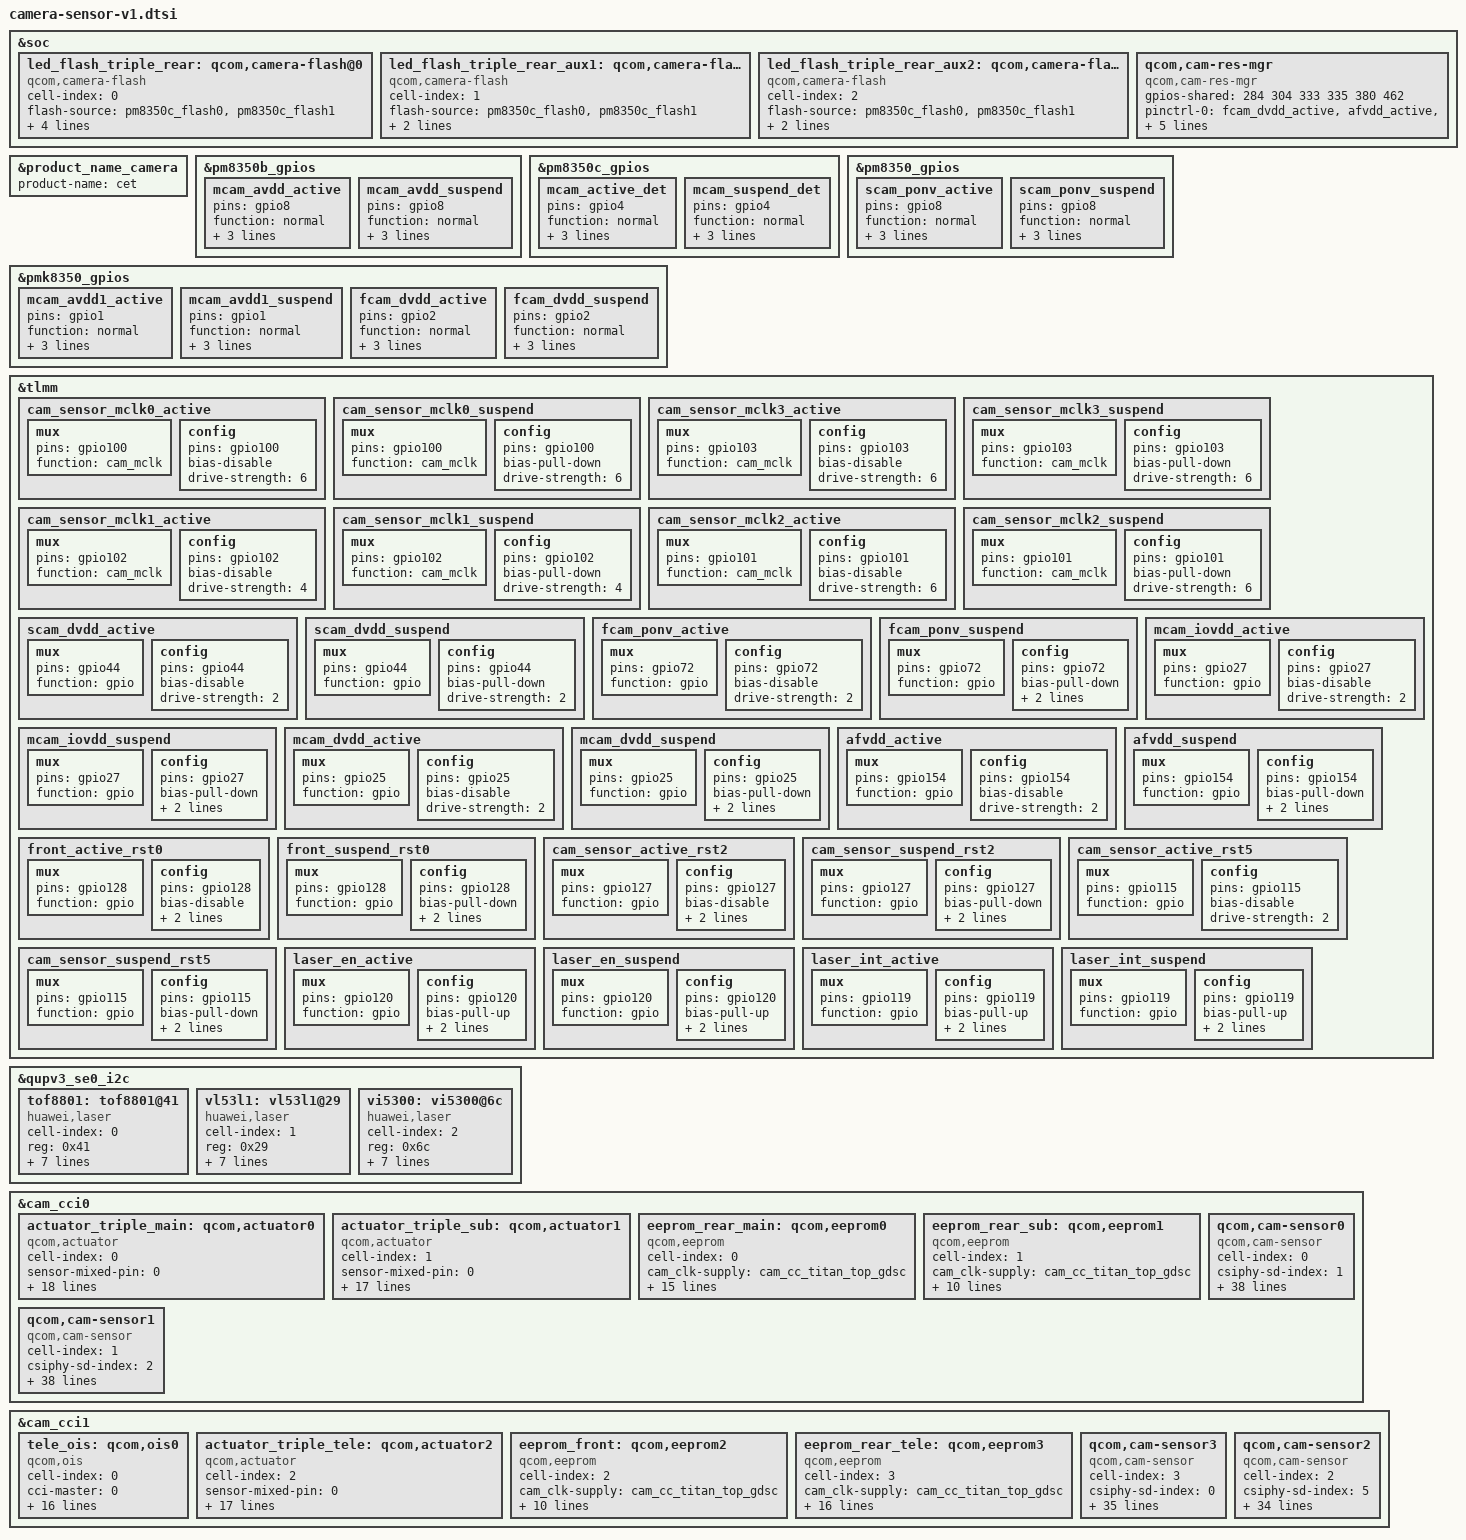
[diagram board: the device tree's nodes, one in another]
#include <dt-bindings/clock/qcom,camcc-lahaina.h>

&soc {
	led_flash_triple_rear: qcom,camera-flash@0 {
		cell-index = <0>;
		compatible = "qcom,camera-flash";
		flash-source = <&pm8350c_flash0 &pm8350c_flash1>;
		torch-source = <&pm8350c_torch0 &pm8350c_torch1>;
		switch-source = <&pm8350c_switch2>;
		torch-light-num = <0 1>;
		torch-light-name = "torch-light0", "torch-light1";
		status = "ok";
	};

	led_flash_triple_rear_aux1: qcom,camera-flash@1 {
		cell-index = <1>;
		compatible = "qcom,camera-flash";
		flash-source = <&pm8350c_flash0 &pm8350c_flash1>;
		torch-source = <&pm8350c_torch0 &pm8350c_torch1>;
		switch-source = <&pm8350c_switch2>;
		status = "ok";
	};

	led_flash_triple_rear_aux2: qcom,camera-flash@2 {
		cell-index = <2>;
		compatible = "qcom,camera-flash";
		flash-source = <&pm8350c_flash0 &pm8350c_flash1>;
		torch-source = <&pm8350c_torch0 &pm8350c_torch1>;
		switch-source = <&pm8350c_switch2>;
		status = "ok";
	};

	qcom,cam-res-mgr {
		compatible = "qcom,cam-res-mgr";
		status = "ok";
		gpios-shared = <284 304 333 335 380 462>;
		pinctrl-names = "cam_active", "cam_suspend";
		pinctrl-0 = <&fcam_dvdd_active
					&afvdd_active
					&mcam_dvdd_active
					&mcam_iovdd_active
					&mcam_avdd_active
					&mcam_avdd1_active>;
		pinctrl-1 = <&fcam_dvdd_suspend
					&afvdd_suspend
					&mcam_dvdd_suspend
					&mcam_iovdd_suspend
					&mcam_avdd_suspend
					&mcam_avdd1_suspend>;
	};
};

&product_name_camera {
    product-name = "cet";
};

&pm8350b_gpios {
	mcam_avdd_active: mcam_avdd_active {
		pins = "gpio8";
		function = "normal";
		bias-disable;
		output-high;
		power-source = <0>;
	};
	mcam_avdd_suspend: mcam_avdd_suspend {
		pins = "gpio8";
		function = "normal";
		bias-disable;
		output-low;
		power-source = <0>;
	};
};

&pm8350c_gpios{
	mcam_active_det: mcam_active_det {
		pins = "gpio4";
		function = "normal";
		bias-disable;
		drive-strength = <2>;
		input-enable;
	};
	mcam_suspend_det: mcam_suspend_det {
		pins = "gpio4";
		function = "normal";
		bias-disable;
		drive-strength = <2>;
		input-enable;
	};
};

&pm8350_gpios {
	scam_ponv_active: scam_ponv_active {
		pins = "gpio8";
		function = "normal";
		bias-disable;
		output-high;
		power-source = <0>;
	};
	scam_ponv_suspend: scam_ponv_suspend {
		pins = "gpio8";
		function = "normal";
		bias-disable;
		output-low;
		power-source = <0>;
	};
};

&pmk8350_gpios {
	mcam_avdd1_active: mcam_avdd1_active {
		pins = "gpio1";
		function = "normal";
		bias-disable;
		output-high;
		power-source = <0>;
	};
	mcam_avdd1_suspend: mcam_avdd1_suspend {
		pins = "gpio1";
		function = "normal";
		bias-disable;
		output-low;
		power-source = <0>;
	};

	fcam_dvdd_active: fcam_dvdd_active {
		pins = "gpio2";
		function = "normal";
		bias-disable;
		output-high;
		power-source = <0>;
	};
	fcam_dvdd_suspend: fcam_dvdd_suspend {
		pins = "gpio2";
		function = "normal";
		bias-disable;
		output-low;
		power-source = <0>;
	};
};

&tlmm {
	cam_sensor_mclk0_active: cam_sensor_mclk0_active {
		/* MCLK0 */
		mux {
			pins = "gpio100";
			function = "cam_mclk";
		};

		config {
			pins = "gpio100";
			bias-disable; /* No PULL */
			drive-strength = <6>; /* 2 MA */
		};
	};

	cam_sensor_mclk0_suspend: cam_sensor_mclk0_suspend {
		/* MCLK0 */
		mux {
			pins = "gpio100";
			function = "cam_mclk";
		};

		config {
			pins = "gpio100";
			bias-pull-down; /* PULL DOWN */
			drive-strength = <6>; /* 2 MA */
		};
	};

	cam_sensor_mclk3_active: cam_sensor_mclk3_active {
		/* MCLK3 */
		mux {
			pins = "gpio103";
			function = "cam_mclk";
		};

		config {
			pins = "gpio103";
			bias-disable; /* No PULL */
			drive-strength = <6>; /* 2 MA */
		};
	};

	cam_sensor_mclk3_suspend: cam_sensor_mclk3_suspend {
		/* MCLK3 */
		mux {
			pins = "gpio103";
			function = "cam_mclk";
		};

		config {
			pins = "gpio103";
			bias-pull-down; /* PULL DOWN */
			drive-strength = <6>; /* 2 MA */
		};
	};

	cam_sensor_mclk1_active: cam_sensor_mclk1_active {
		/* MCLK1 */
		mux {
			pins = "gpio102";
			function = "cam_mclk";
		};

		config {
			pins = "gpio102";
			bias-disable; /* No PULL */
			drive-strength = <4>; /* 2 MA */
		};
	};

	cam_sensor_mclk1_suspend: cam_sensor_mclk1_suspend {
		/* MCLK1 */
		mux {
			pins = "gpio102";
			function = "cam_mclk";
		};

		config {
			pins = "gpio102";
			bias-pull-down; /* PULL DOWN */
			drive-strength = <4>; /* 2 MA */
		};
	};

	cam_sensor_mclk2_active: cam_sensor_mclk2_active {
		/* MCLK2 */
		mux {
			pins = "gpio101";
			function = "cam_mclk";
		};

		config {
			pins = "gpio101";
			bias-disable; /* No PULL */
			drive-strength = <6>; /* 2 MA */
		};
	};

	cam_sensor_mclk2_suspend: cam_sensor_mclk2_suspend {
		/* MCLK2 */
		mux {
			pins = "gpio101";
			function = "cam_mclk";
		};

		config {
			pins = "gpio101";
			bias-pull-down; /* PULL DOWN */
			drive-strength = <6>; /* 2 MA */
		};
	};

	scam_dvdd_active: scam_dvdd_active {
		/* DVDD 0-for main */
		mux {
			pins = "gpio44";
			function = "gpio";
		};

		config {
			pins = "gpio44";
			bias-disable; /* No PULL */
			drive-strength = <2>; /* 2 MA */
		};
	};

	scam_dvdd_suspend: scam_dvdd_suspend {
		/* DVDD 0-for main */
		mux {
			pins = "gpio44";
			function = "gpio";
		};

		config {
			pins = "gpio44";
			bias-pull-down; /* PULL DOWN */
			drive-strength = <2>; /* 2 MA */
		};
	};


	fcam_ponv_active: fcam_ponv_active {
		/* fcam ponv */
		mux {
			pins = "gpio72";
			function = "gpio";
		};

		config {
			pins = "gpio72";
			bias-disable; /* No PULL */
			drive-strength = <2>; /* 2 MA */
		};
	};

	fcam_ponv_suspend: fcam_ponv_suspend {
		/* fcam ponv */
		mux {
			pins = "gpio72";
			function = "gpio";
		};

		config {
			pins = "gpio72";
			bias-pull-down; /* PULL DOWN */
			drive-strength = <2>; /* 2 MA */
			output-low;
		};
	};

	mcam_iovdd_active: mcam_iovdd_active {
		mux {
			pins = "gpio27";
			function = "gpio";
		};

		config {
			pins = "gpio27";
			bias-disable; /* No PULL */
			drive-strength = <2>; /* 2 MA */
		};
	};

	mcam_iovdd_suspend: mcam_iovdd_suspend {
		mux {
			pins = "gpio27";
			function = "gpio";
		};

		config {
			pins = "gpio27";
			bias-pull-down; /* PULL DOWN */
			drive-strength = <2>; /* 2 MA */
			output-low;
		};
	};

	mcam_dvdd_active: mcam_dvdd_active {
		mux {
			pins = "gpio25";
			function = "gpio";
		};

		config {
			pins = "gpio25";
			bias-disable; /* No PULL */
			drive-strength = <2>; /* 2 MA */
		};
	};

	mcam_dvdd_suspend: mcam_dvdd_suspend {
		mux {
			pins = "gpio25";
			function = "gpio";
		};

		config {
			pins = "gpio25";
			bias-pull-down; /* PULL DOWN */
			drive-strength = <2>; /* 2 MA */
			output-low;
		};
	};

	afvdd_active: afvdd_active {
		mux {
			pins = "gpio154";
			function = "gpio";
		};

		config {
			pins = "gpio154";
			bias-disable; /* No PULL */
			drive-strength = <2>; /* 2 MA */
		};
	};

	afvdd_suspend: afvdd_suspend {
		mux {
			pins = "gpio154";
			function = "gpio";
		};

		config {
			pins = "gpio154";
			bias-pull-down; /* PULL DOWN */
			drive-strength = <2>; /* 2 MA */
			output-low;
		};
	};

	front_active_rst0: front_active_rst0 {
		/* RESET 0 */
		mux {
			pins = "gpio128";
			function = "gpio";
		};

		config {
			pins = "gpio128";
			bias-disable; /* No PULL */
			drive-strength = <2>; /* 2 MA */
			input-enable;
		};
	};

	front_suspend_rst0: front_suspend_rst0 {
		/* RESET 0 */
		mux {
			pins = "gpio128";
			function = "gpio";
		};

		config {
			pins = "gpio128";
			bias-pull-down; /* PULL DOWN */
			drive-strength = <2>; /* 2 MA */
			output-low;
		};
	};

	cam_sensor_active_rst2: cam_sensor_active_rst2 {
		/* RESET 2 */
		mux {
			pins = "gpio127";
			function = "gpio";
		};

		config {
			pins = "gpio127";
			bias-disable; /* No PULL */
			drive-strength = <2>; /* 2 MA */
			input-enable;
		};
	};

	cam_sensor_suspend_rst2: cam_sensor_suspend_rst2 {
		/* RESET 2 */
		mux {
			pins = "gpio127";
			function = "gpio";
		};

		config {
			pins = "gpio127";
			bias-pull-down; /* PULL DOWN */
			drive-strength = <2>; /* 2 MA */
			output-low;
		};
	};

	cam_sensor_active_rst5: cam_sensor_active_rst5 {
		/* RESET 5 */
		mux {
			pins = "gpio115";
			function = "gpio";
		};

		config {
			pins = "gpio115";
			bias-disable; /* No PULL */
			drive-strength = <2>; /* 2 MA */
		};
	};

	cam_sensor_suspend_rst5: cam_sensor_suspend_rst5 {
		/* RESET 2 */
		mux {
			pins = "gpio115";
			function = "gpio";
		};

		config {
			pins = "gpio115";
			bias-pull-down; /* PULL DOWN */
			drive-strength = <2>; /* 2 MA */
			output-low;
		};
	};

	laser_en_active: laser_en_active {
		/* laser en pin */
		mux {
			pins = "gpio120";
			function = "gpio";
		};

		config {
			pins = "gpio120";
			bias-pull-up; /* PULL UP */
			drive-strength = <2>; /* 2 MA */
			input-enable;
		};
	};

	laser_en_suspend: laser_en_suspend {
		/* laser en pin */
		mux {
			pins = "gpio120";
			function = "gpio";
		};

		config {
			pins = "gpio120";
			bias-pull-up; /* PULL UP */
			drive-strength = <2>; /* 2 MA */
			input-enable;
		};
	};

	laser_int_active: laser_int_active {
		/* laser int pin */
		mux {
			pins = "gpio119";
			function = "gpio";
		};

		config {
			pins = "gpio119";
			bias-pull-up; /* PULL UP */
			drive-strength = <2>; /* 2 MA */
			input-enable;
		};
	};

	laser_int_suspend: laser_int_suspend {
		/* laser int pin */
		mux {
			pins = "gpio119";
			function = "gpio";
		};

		config {
			pins = "gpio119";
			bias-pull-up; /* PULL UP */
			drive-strength = <2>; /* 2 MA */
			input-enable;
		};
	};
};

/* laser */
&qupv3_se0_i2c {
	status = "ok";
	#address-cells = <1>;
	#size-cells = <0>;

	tof8801: tof8801@41 {
		cell-index = <0>;
		compatible = "huawei,laser";
		reg = <0x41>;
		vdd_ana-supply = <&pm8350_l7>;
		gpios = <&tlmm 120 0>,
			<&tlmm 119 0>;
		pinctrl-names = "laser_int_active", "laser_en_active";
		pinctrl-0 = <&laser_int_active>;
		pinctrl-1 = <&laser_en_active>;
		gpio-req-tbl-num = <0>;
		gpio-req-tbl-flags = <0>;
		gpio-req-tbl-label = "CAM_VAF0";
		status = "ok";
	};

	vl53l1: vl53l1@29 {
		cell-index = <1>;
		compatible = "huawei,laser";
		reg = <0x29>;
		vdd_ana-supply = <&pm8350_l7>;
		gpios = <&tlmm 120 0>,
			<&tlmm 119 0>;
		pinctrl-names = "laser_int_active", "laser_en_active";
		pinctrl-0 = <&laser_int_active>;
		pinctrl-1 = <&laser_en_active>;
		gpio-req-tbl-num = <0>;
		gpio-req-tbl-flags = <0>;
		gpio-req-tbl-label = "CAM_VAF0";
		status = "ok";
	};

	vi5300: vi5300@6c {
		cell-index = <2>;
		compatible = "huawei,laser";
		reg = <0x6c>;
		vdd_ana-supply = <&pm8350_l7>;
		gpios = <&tlmm 120 0>,
			<&tlmm 119 0>;
		pinctrl-names = "laser_int_active", "laser_en_active";
		pinctrl-0 = <&laser_int_active>;
		pinctrl-1 = <&laser_en_active>;
		gpio-req-tbl-num = <0>;
		gpio-req-tbl-flags = <0>;
		gpio-req-tbl-label = "CAM_VAF0";
		status = "ok";
	};
};

&cam_cci0 {
	actuator_triple_main: qcom,actuator0 {
		cell-index = <0>;
		compatible = "qcom,actuator";
		sensor-mixed-pin = <0>;
		cam_clk-supply = <&cam_cc_titan_top_gdsc>;
		regulator-names = "cam_clk";
		rgltr-cntrl-support;
		5v_boost_support;
		rgltr-min-voltage = <0>;
		rgltr-max-voltage = <0>;
		rgltr-load-current = <0>;
		gpio-no-mux = <0>;
		gpios = <&tlmm 27 0>,
			<&tlmm 154 0>;
		gpio-mixed1 = <0>;
		gpio-mixed2 = <1>;
		gpio-req-tbl-num = <0 1>;
		gpio-req-tbl-flags = <0 0>;
		gpio-req-tbl-label = "IO_VDD",
					"AFVDD";
		cci-master = <0>;
		status = "ok";
		clocks = <&clock_camcc CAM_CC_MCLK0_CLK>;
		clock-names = "cam_clk";
		clock-cntl-level = "nominal";
		clock-rates = <19200000>;
	};

	actuator_triple_sub: qcom,actuator1 {
		cell-index = <1>;
		compatible = "qcom,actuator";
		sensor-mixed-pin = <0>;
		cam_clk-supply = <&cam_cc_titan_top_gdsc>;
		regulator-names = "cam_clk";
		rgltr-cntrl-support;
		5v_boost_support;
		rgltr-min-voltage = <0>;
		rgltr-max-voltage = <0>;
		rgltr-load-current = <0>;
		gpio-no-mux = <0>;
		gpios = <&tlmm 154 0>;
		gpio-mixed1 = <0>;
		gpio-req-tbl-num = <0>;
		gpio-req-tbl-flags = <0>;
		gpio-req-tbl-label = "AFVDD";
		cci-master = <1>;
		status = "ok";
		clocks = <&clock_camcc CAM_CC_MCLK2_CLK>;
		clock-names = "cam_clk";
		clock-cntl-level = "nominal";
		clock-rates = <19200000>;
	};
	eeprom_rear_main: qcom,eeprom0 {
		cell-index = <0>;
		compatible = "qcom,eeprom";
		cam_clk-supply = <&cam_cc_titan_top_gdsc>;
		regulator-names = "cam_clk";
		rgltr-cntrl-support;
		rgltr-min-voltage = <0>;
		rgltr-max-voltage = <0>;
		rgltr-load-current = <0>;
		gpio-no-mux = <0>;
		gpios = <&tlmm 27 0>;
		gpio-mixed1 = <0>;
		gpio-req-tbl-num = <0>;
		gpio-req-tbl-flags = <0>;
		gpio-req-tbl-label = "CAM_VIO";
		cci-master = <0>;
		status = "ok";
		clocks = <&clock_camcc CAM_CC_MCLK0_CLK>;
		clock-names = "cam_clk";
		clock-cntl-level = "nominal";
		clock-rates = <19200000>;
	};

	eeprom_rear_sub: qcom,eeprom1 {
		cell-index = <1>;
		compatible = "qcom,eeprom";
		cam_clk-supply = <&cam_cc_titan_top_gdsc>;
		regulator-names = "cam_clk";
		rgltr-cntrl-support;
		rgltr-min-voltage = <0>;
		rgltr-max-voltage = <0>;
		rgltr-load-current = <0>;
		gpio-no-mux = <0>;
		cci-master = <1>;
		status = "ok";
		clocks = <&clock_camcc CAM_CC_MCLK2_CLK>;
		clock-names = "cam_clk";
		clock-cntl-level = "nominal";
		clock-rates = <19200000>;
	};
	/* back main sensor */
	qcom,cam-sensor0 {
		cell-index = <0>;
		compatible = "qcom,cam-sensor";
		csiphy-sd-index = <1>;
		sensor-mixed-pin = <0>;
		sensor-position-roll = <90>;
		sensor-position-pitch = <0>;
		sensor-position-yaw = <180>;
		eeprom-src = <&eeprom_rear_main>;
		actuator-src = <&actuator_triple_main>;
		led-flash-src = <&led_flash_triple_rear>;
		cam_clk-supply = <&cam_cc_titan_top_gdsc>;
		regulator-names = "cam_clk";
		rgltr-cntrl-support;
		5v_boost_support;
		btb_check_support;
		rgltr-min-voltage = <0>;
		rgltr-max-voltage = <0>;
		rgltr-load-current = <0>;
		gpio-no-mux = <0>;
		pinctrl-names = "cam_default", "cam_suspend";
		pinctrl-0 = <&cam_sensor_mclk0_active
				&cam_sensor_active_rst1
				&mcam_active_det>;
		pinctrl-1 = <&cam_sensor_mclk0_suspend
				&cam_sensor_suspend_rst1
				&mcam_suspend_det>;
		gpios = <&tlmm 100 0>,
			<&tlmm 16 0>,
			<&pm8350b_gpios 8 0>,
			<&pmk8350_gpios 1 0>,
			<&tlmm 25 0>,
			<&tlmm 27 0>,
			<&pm8350c_gpios 4 0>;
		gpio-reset = <1>;
		gpio-mixed1 = <2>;
		gpio-mixed2 = <3>;
		gpio-mixed3 = <4>;
		gpio-mixed4 = <5>;
		gpio-btb-det = <6>;
		gpio-req-tbl-num = <0 1 2 3 4 5 6>;
		gpio-req-tbl-flags = <1 0 0 0 0 0 0>;
		gpio-req-tbl-label = "CAM_MCLK0",
					"CAM_RESET",
					"CAM_AVDD2-85",
					"CAM_AVDD1-8",
					"CAM_DVDD",
					"CAM_VIO",
					"CAM_BTB_DET";
		cci-master = <0>;
		status = "ok";
		clocks = <&clock_camcc CAM_CC_MCLK0_CLK>;
		clock-names = "cam_clk";
		clock-cntl-level = "nominal";
		clock-rates = <19200000>;
	};

	/* back wide sensor */
	qcom,cam-sensor1 {
		cell-index = <1>;
		compatible = "qcom,cam-sensor";
		csiphy-sd-index = <2>;
		sensor-mixed-pin = <0>;
		sensor-position-roll = <90>;
		sensor-position-pitch = <0>;
		sensor-position-yaw = <180>;
		actuator-src = <&actuator_triple_sub>;
		eeprom-src = <&eeprom_rear_sub>;
		led-flash-src = <&led_flash_triple_rear_aux1>;
		cam_clk-supply = <&cam_cc_titan_top_gdsc>;
		regulator-names = "cam_clk";
		rgltr-cntrl-support;
		5v_boost_support;
		btb_check_support;
		rgltr-min-voltage = <0>;
		rgltr-max-voltage = <0>;
		rgltr-load-current = <0>;
		gpio-no-mux = <0>;
		pinctrl-names = "cam_default", "cam_suspend";
		pinctrl-0 = <&cam_sensor_mclk1_active
				&scam_dvdd_active
				&scam_ponv_active
				&cam_sensor_active_rst2>;
		pinctrl-1 = <&cam_sensor_mclk1_suspend
				&scam_dvdd_suspend
				&scam_ponv_suspend
				&cam_sensor_suspend_rst2>;
		gpios = <&tlmm 102 0>,
			<&tlmm 127 0>,
			<&pm8350b_gpios 8 0>,
			<&tlmm 44 0>,
			<&pmk8350_gpios 1 0>,
			<&pm8350_gpios 8 0>;
		gpio-reset = <1>;
		gpio-mixed1 = <2>;
		gpio-mixed2 = <3>;
		gpio-mixed3 = <4>;
		gpio-mixed4 = <5>;
		gpio-req-tbl-num = <0 1 2 3 4 5>;
		gpio-req-tbl-flags = <1 0 0 0 0 0>;
		gpio-req-tbl-label = "CAMIF_MCLK1",
					"CAM_RESET2",
					"CAM_AVDD2-85",
					"CAM_DVDD",
					"CAM_AVDD1-8",
					"CAM_PONV";
		cci-master = <1>;
		status = "ok";
		clocks = <&clock_camcc CAM_CC_MCLK2_CLK>;
		clock-names = "cam_clk";
		clock-cntl-level = "nominal";
		clock-rates = <19200000>;
	};
};

&cam_cci1 {
	tele_ois: qcom,ois0 {
		cell-index = <0>;
		compatible = "qcom,ois";
		cci-master = <0>;
		cam_clk-supply = <&cam_cc_titan_top_gdsc>;
		regulator-names = "cam_clk";
		rgltr-cntrl-support;
		5v_boost_support;
		rgltr-min-voltage = <0>;
		rgltr-max-voltage = <0>;
		rgltr-load-current = <0>;
		gpio-no-mux = <0>;
		gpios = <&tlmm 154 0>;
		gpio-mixed1 = <0>;
		gpio-req-tbl-num = <0>;
		gpio-req-tbl-flags = <0>;
		gpio-req-tbl-label = "DRVDD";
		status = "ok";
		clocks = <&clock_camcc CAM_CC_MCLK1_CLK>;
		clock-names = "cam_clk";
		clock-cntl-level = "nominal";
		clock-rates = <19200000>;
	};

	actuator_triple_tele: qcom,actuator2 {
		cell-index = <2>;
		compatible = "qcom,actuator";
		sensor-mixed-pin = <0>;
		cam_clk-supply = <&cam_cc_titan_top_gdsc>;
		regulator-names = "cam_clk";
		rgltr-cntrl-support;
		5v_boost_support;
		rgltr-min-voltage = <0>;
		rgltr-max-voltage = <0>;
		rgltr-load-current = <0>;
		gpio-no-mux = <0>;
		gpios = <&tlmm 154 0>;
		gpio-mixed1 = <0>;
		gpio-req-tbl-num = <0>;
		gpio-req-tbl-flags = <0>;
		gpio-req-tbl-label = "AFVDD";
		cci-master = <0>;
		status = "ok";
		clocks = <&clock_camcc CAM_CC_MCLK1_CLK>;
		clock-names = "cam_clk";
		clock-cntl-level = "nominal";
		clock-rates = <19200000>;
	};
	eeprom_front: qcom,eeprom2 {
		cell-index = <2>;
		compatible = "qcom,eeprom";
		cam_clk-supply = <&cam_cc_titan_top_gdsc>;
		regulator-names = "cam_clk";
		rgltr-cntrl-support;
		rgltr-min-voltage = <0>;
		rgltr-max-voltage = <0>;
		rgltr-load-current = <0>;
		gpio-no-mux = <0>;
		cci-master = <1>;
		status = "ok";
		clocks = <&clock_camcc CAM_CC_MCLK3_CLK>;
		clock-names = "cam_clk";
		clock-cntl-level = "nominal";
		clock-rates = <19200000>;
	};

	eeprom_rear_tele: qcom,eeprom3 {
		cell-index = <3>;
		compatible = "qcom,eeprom";
		cam_clk-supply = <&cam_cc_titan_top_gdsc>;
		regulator-names = "cam_clk";
		rgltr-cntrl-support;
		rgltr-min-voltage = <0>;
		rgltr-max-voltage = <0>;
		rgltr-load-current = <0>;
		gpio-no-mux = <0>;
		gpios = <&tlmm 27 0>,
				<&tlmm 154 0>;
		gpio-mixed1 = <0>;
		gpio-mixed2 = <1>;
		gpio-req-tbl-num = <0 1>;
		gpio-req-tbl-flags = <0 0>;
		gpio-req-tbl-label = "CAM_VIO", "DRVDD";
		cci-master = <0>;
		status = "ok";
		clocks = <&clock_camcc CAM_CC_MCLK1_CLK>;
		clock-names = "cam_clk";
		clock-cntl-level = "nominal";
		clock-rates = <19200000>;
	};
	/* back tele sensor */
	qcom,cam-sensor3 {
		cell-index = <3>;
		compatible = "qcom,cam-sensor";
		csiphy-sd-index = <0>;
		sensor-mixed-pin = <0>;
		sensor-position-roll = <90>;
		sensor-position-pitch = <0>;
		sensor-position-yaw = <180>;
		actuator-src = <&actuator_triple_tele>;
		eeprom-src = <&eeprom_rear_tele>;
		ois-src  = <&tele_ois>;
		led-flash-src = <&led_flash_triple_rear_aux2>;
		cam_clk-supply = <&cam_cc_titan_top_gdsc>;
		regulator-names = "cam_clk";
		rgltr-cntrl-support;
		5v_boost_support;
		rgltr-min-voltage = <0>;
		rgltr-max-voltage = <0>;
		rgltr-load-current = <0>;
		gpio-no-mux = <0>;
		pinctrl-names = "cam_default", "cam_suspend";
		pinctrl-0 = <&cam_sensor_mclk2_active
					&cam_sensor_active_rst5>;
		pinctrl-1 = <&cam_sensor_mclk2_suspend
					&cam_sensor_suspend_rst5>;
		gpios = <&tlmm 101 0>,
			<&tlmm 115 0>,
			<&pm8350b_gpios 8 0>,
			<&tlmm 25 0>,
			<&tlmm 27 0>,
			<&pmk8350_gpios 1 0>;
		gpio-reset = <1>;
		gpio-mixed1 = <2>;
		gpio-mixed2 = <3>;
		gpio-mixed3 = <4>;
		gpio-mixed4 = <5>;
		gpio-req-tbl-num = <0 1 2 3 4 5>;
		gpio-req-tbl-flags = <1 0 0 0 0 0>;
		gpio-req-tbl-label = "CAMIF_MCLK2",
					"CAM_RESET3",
					"CAM_AVDD2-85",
					"CAM_DVDD",
					"CAM_VIO",
					"CAM_AVDD1-8";
		cci-master = <0>;
		status = "ok";
		clocks = <&clock_camcc CAM_CC_MCLK1_CLK>;
		clock-names = "cam_clk";
		clock-cntl-level = "nominal";
		clock-rates = <19200000>;
	};

	/* front main sensor */
	qcom,cam-sensor2 {
		cell-index = <2>;
		compatible = "qcom,cam-sensor";
		csiphy-sd-index = <5>;
		sensor-mixed-pin = <0>;
		sensor-position-roll = <270>;
		sensor-position-pitch = <0>;
		sensor-position-yaw = <0>;
		/* actuator-src = <&actuator_front>; */
		eeprom-src = <&eeprom_front>;
		cam_clk-supply = <&cam_cc_titan_top_gdsc>;
		regulator-names = "cam_clk";
		rgltr-cntrl-support;
		5v_boost_support;
		btb_check_support;
		rgltr-min-voltage = <0>;
		rgltr-max-voltage = <0>;
		rgltr-load-current = <0>;
		gpio-no-mux = <0>;
		pinctrl-names = "cam_default", "cam_suspend";
		pinctrl-0 = <&cam_sensor_mclk3_active
				&fcam_ponv_active
				&front_active_rst0>;
		pinctrl-1 = <&cam_sensor_mclk3_suspend
				&fcam_ponv_suspend
				&front_suspend_rst0>;
		gpios = <&tlmm 103 0>,
			<&tlmm 128 0>,
			<&pm8350b_gpios 8 0>,
			<&pmk8350_gpios 1 0>,
			<&pmk8350_gpios 2 0>,
			<&tlmm 72 0>;
		gpio-reset = <1>;
		gpio-mixed1 = <2>;
		gpio-mixed2 = <3>;
		gpio-mixed3 = <4>;
		gpio-mixed4 = <5>;
		gpio-req-tbl-num = <0 1 2 3 4 5>;
		gpio-req-tbl-flags = <1 0 0 0 0 0>;
		gpio-req-tbl-label = "CAMIF_MCLK2",
					"CAM_RESET2",
					"CAM_AVDD2-85",
					"CAM_AVDD1-8",
					"CAM_DVDD",
					"CAM_PONV";
		cci-master = <1>;
		status = "ok";
		clocks = <&clock_camcc CAM_CC_MCLK3_CLK>;
		clock-names = "cam_clk";
		clock-cntl-level = "nominal";
		clock-rates = <19200000>;
	};
};
